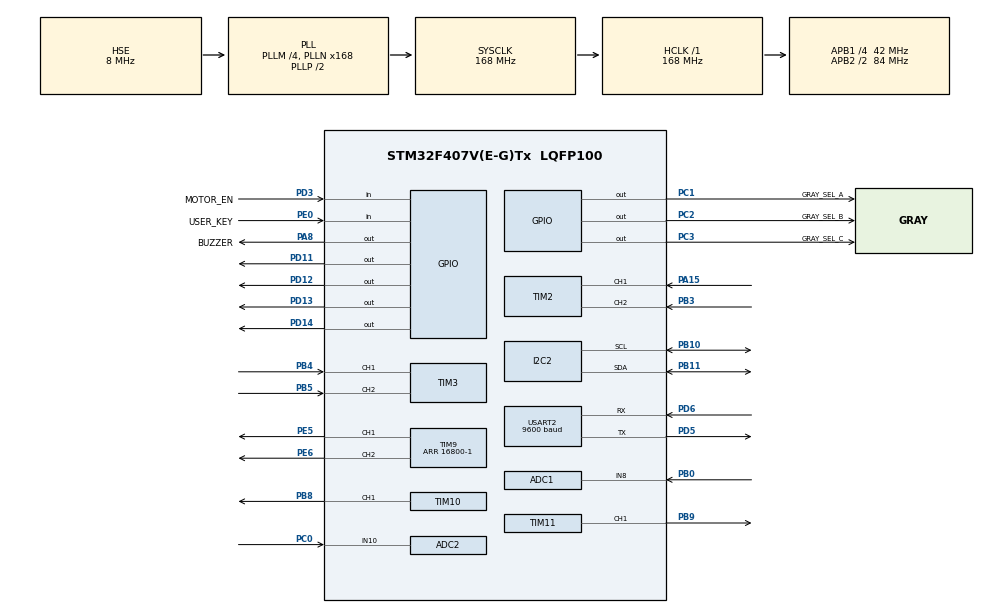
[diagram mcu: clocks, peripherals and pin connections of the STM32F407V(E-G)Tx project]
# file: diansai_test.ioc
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ADC1.Channel-9\#ChannelRegularConversion=ADC_CHANNEL_8
ADC1.NbrOfConversionFlag=1
ADC1.Rank-9\#ChannelRegularConversion=1
ADC1.SamplingTime-9\#ChannelRegularConversion=ADC_SAMPLETIME_144CYCLES
ADC1.master=1
ADC2.Channel-10\#ChannelRegularConversion=ADC_CHANNEL_10
ADC2.NbrOfConversionFlag=1
ADC2.Rank-10\#ChannelRegularConversion=1
ADC2.SamplingTime-10\#ChannelRegularConversion=ADC_SAMPLETIME_144CYCLES
ADC2.master=1
Mcu.Family=STM32F4
Mcu.Name=STM32F407V(E-G)Tx
Mcu.Package=LQFP100
NVIC.PriorityGroup=NVIC_PRIORITYGROUP_4
NVIC.USART2_IRQn=true\:0\:0\:false\:false\:true\:true\:true\:true
PA13.Mode=Serial_Wire
PA13.Signal=SYS_JTMS-SWDIO
PA14.Mode=Serial_Wire
PA14.Signal=SYS_JTCK-SWCLK
PA15.Signal=S_TIM2_CH1_ETR
PA8.GPIO_Label=BUZZER
PA8.PinState=GPIO_PIN_RESET
PA8.Signal=GPIO_Output
PB0.Signal=ADCx_IN8
PB10.Mode=I2C
PB10.GPIO_PuPd=GPIO_PULLUP
PB10.Signal=I2C2_SCL
PB11.Mode=I2C
PB11.GPIO_PuPd=GPIO_PULLUP
PB11.Signal=I2C2_SDA
PB3.Signal=S_TIM2_CH2
PB4.Signal=S_TIM3_CH1
PB5.Signal=S_TIM3_CH2
PB8.Signal=S_TIM10_CH1
PB9.Signal=S_TIM11_CH1
PC0.Signal=ADCx_IN10
PC1.GPIO_Label=GRAY_SEL_A
PC1.PinState=GPIO_PIN_RESET
PC1.Signal=GPIO_Output
PC2.GPIO_Label=GRAY_SEL_B
PC2.PinState=GPIO_PIN_RESET
PC2.Signal=GPIO_Output
PC3.GPIO_Label=GRAY_SEL_C
PC3.PinState=GPIO_PIN_RESET
PC3.Signal=GPIO_Output
PD11.PinState=GPIO_PIN_RESET
PD11.Signal=GPIO_Output
PD12.PinState=GPIO_PIN_SET
PD12.Signal=GPIO_Output
PD13.PinState=GPIO_PIN_SET
PD13.Signal=GPIO_Output
PD14.PinState=GPIO_PIN_SET
PD14.Signal=GPIO_Output
PD3.GPIO_Label=MOTOR_EN
PD3.GPIO_PuPd=GPIO_PULLUP
PD3.Signal=GPIO_Input
PD5.Mode=Asynchronous
PD5.Signal=USART2_TX
PD6.Mode=Asynchronous
PD6.Signal=USART2_RX
PE0.GPIO_Label=USER_KEY
PE0.GPIO_PuPd=GPIO_PULLUP
PE0.Signal=GPIO_Input
PE5.Signal=S_TIM9_CH1
PE6.Signal=S_TIM9_CH2
PH0-OSC_IN.Mode=HSE-External-Oscillator
PH0-OSC_IN.Signal=RCC_OSC_IN
PH1-OSC_OUT.Mode=HSE-External-Oscillator
PH1-OSC_OUT.Signal=RCC_OSC_OUT
ProjectManager.HeapSize=0x200
ProjectManager.StackSize=0x400
ProjectManager.TargetToolchain=MDK-ARM V5
RCC.48MHZClocksFreq_Value=84000000
RCC.AHBFreq_Value=168000000
RCC.APB1CLKDivider=RCC_HCLK_DIV4
RCC.APB1Freq_Value=42000000
RCC.APB1TimFreq_Value=84000000
RCC.APB2CLKDivider=RCC_HCLK_DIV2
RCC.APB2Freq_Value=84000000
RCC.APB2TimFreq_Value=168000000
RCC.CortexFreq_Value=168000000
RCC.HCLKFreq_Value=168000000
RCC.HSE_VALUE=8000000
RCC.HSI_VALUE=16000000
RCC.LSE_VALUE=32768
RCC.PLLM=4
RCC.PLLN=168
RCC.PLLSourceVirtual=RCC_PLLSOURCE_HSE
RCC.SYSCLKFreq_VALUE=168000000
RCC.SYSCLKSource=RCC_SYSCLKSOURCE_PLLCLK
RCC.VCOOutputFreq_Value=336000000
SH.ADCx_IN8.0=ADC1_IN8,IN8
SH.ADCx_IN10.0=ADC2_IN10,IN10
SH.S_TIM10_CH1.0=TIM10_CH1,PWM Generation1 CH1
SH.S_TIM11_CH1.0=TIM11_CH1,PWM Generation1 CH1
SH.S_TIM2_CH1_ETR.0=TIM2_CH1,Encoder_Interface
SH.S_TIM2_CH2.0=TIM2_CH2,Encoder_Interface
SH.S_TIM3_CH1.0=TIM3_CH1,Encoder_Interface
SH.S_TIM3_CH2.0=TIM3_CH2,Encoder_Interface
SH.S_TIM9_CH1.0=TIM9_CH1,PWM Generation1 CH1
SH.S_TIM9_CH2.0=TIM9_CH2,PWM Generation2 CH2
TIM10.Channel=TIM_CHANNEL_1
TIM10.Period=16800-1
TIM11.Channel=TIM_CHANNEL_1
TIM11.Period=16800-1
TIM2.EncoderMode=TIM_ENCODERMODE_TI12
TIM3.EncoderMode=TIM_ENCODERMODE_TI12
TIM9.Channel-PWM\ Generation1\ CH1=TIM_CHANNEL_1
TIM9.Channel-PWM\ Generation2\ CH2=TIM_CHANNEL_2
TIM9.Period=16800-1
USART2.BaudRate=9600
USART2.VirtualMode=VM_ASYNC
VP_TIM10_VS_ClockSourceINT.Mode=Enable_Timer
VP_TIM11_VS_ClockSourceINT.Mode=Enable_Timer
VP_TIM9_VS_ClockSourceINT.Mode=Internal
board=custom

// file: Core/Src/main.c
/* USER CODE BEGIN Header */
/**
  ******************************************************************************
  * @file           : main.c
  * @brief          : Main program body
  ******************************************************************************
  */
/* USER CODE END Header */
#include "main.h"
#include "adc.h"
#include "i2c.h"
#include "tim.h"
#include "usart.h"
#include "gpio.h"

/* USER CODE BEGIN Includes */
#include "vehicle_app.h"
/* USER CODE END Includes */

void SystemClock_Config(void);

int main(void)
{

  /* MCU Configuration--------------------------------------------------------*/

  /* Reset of all peripherals, Initializes the Flash interface and the Systick. */
  HAL_Init();

  /* Configure the system clock */
  SystemClock_Config();

  /* Initialize all configured peripherals */
  MX_GPIO_Init();
  MX_TIM2_Init();
  MX_TIM3_Init();
  MX_TIM9_Init();
  MX_TIM10_Init();
  MX_TIM11_Init();
  MX_I2C2_Init();
  MX_USART2_UART_Init();
  MX_ADC1_Init();
  MX_ADC2_Init();
  /* USER CODE BEGIN 2 */
  Vehicle_Init();
  /* USER CODE END 2 */

  /* Infinite loop */
  /* USER CODE BEGIN WHILE */
  while (1)
  {
    Vehicle_Loop();
    /* USER CODE END WHILE */

  }
}

void SystemClock_Config(void)
{
  RCC_OscInitTypeDef RCC_OscInitStruct = {0};
  RCC_ClkInitTypeDef RCC_ClkInitStruct = {0};

  /** Configure the main internal regulator output voltage
  */
  __HAL_RCC_PWR_CLK_ENABLE();
  __HAL_PWR_VOLTAGESCALING_CONFIG(PWR_REGULATOR_VOLTAGE_SCALE1);

  /** Initializes the RCC Oscillators according to the specified parameters
  * in the RCC_OscInitTypeDef structure.
  */
  RCC_OscInitStruct.OscillatorType = RCC_OSCILLATORTYPE_HSE;
  RCC_OscInitStruct.HSEState = RCC_HSE_ON;
  RCC_OscInitStruct.PLL.PLLState = RCC_PLL_ON;
  RCC_OscInitStruct.PLL.PLLSource = RCC_PLLSOURCE_HSE;
  RCC_OscInitStruct.PLL.PLLM = 4;
  RCC_OscInitStruct.PLL.PLLN = 168;
  RCC_OscInitStruct.PLL.PLLP = RCC_PLLP_DIV2;
  RCC_OscInitStruct.PLL.PLLQ = 4;
  if (HAL_RCC_OscConfig(&RCC_OscInitStruct) != HAL_OK)
  {
    Error_Handler();
  }

  /** Initializes the CPU, AHB and APB buses clocks
  */
  RCC_ClkInitStruct.ClockType = RCC_CLOCKTYPE_HCLK|RCC_CLOCKTYPE_SYSCLK
                              |RCC_CLOCKTYPE_PCLK1|RCC_CLOCKTYPE_PCLK2;
  RCC_ClkInitStruct.SYSCLKSource = RCC_SYSCLKSOURCE_PLLCLK;
  RCC_ClkInitStruct.AHBCLKDivider = RCC_SYSCLK_DIV1;
  RCC_ClkInitStruct.APB1CLKDivider = RCC_HCLK_DIV4;
  RCC_ClkInitStruct.APB2CLKDivider = RCC_HCLK_DIV2;

  if (HAL_RCC_ClockConfig(&RCC_ClkInitStruct, FLASH_LATENCY_5) != HAL_OK)
  {
    Error_Handler();
  }
}

void Error_Handler(void)
{
  __disable_irq();
  while (1)
  {
  }
}
